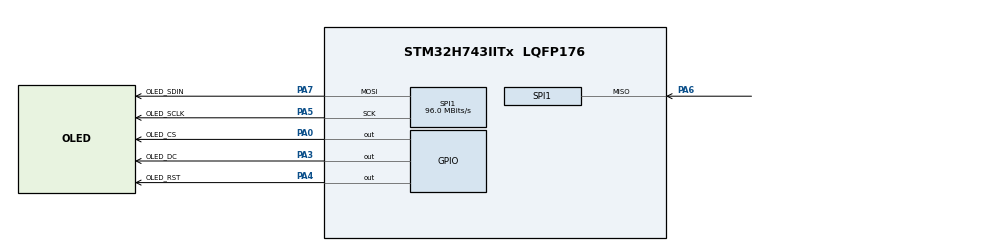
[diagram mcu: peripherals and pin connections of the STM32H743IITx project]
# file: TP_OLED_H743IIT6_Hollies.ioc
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ADC3.Channel-0\#ChannelRegularConversion=ADC_CHANNEL_TEMPSENSOR
ADC3.NbrOfConversion=1
ADC3.NbrOfConversionFlag=1
ADC3.OffsetNumber-0\#ChannelRegularConversion=ADC_OFFSET_NONE
ADC3.OffsetSignedSaturation-0\#ChannelRegularConversion=DISABLE
ADC3.Rank-0\#ChannelRegularConversion=1
ADC3.Resolution=ADC_RESOLUTION_16B
ADC3.SamplingTime-0\#ChannelRegularConversion=ADC_SAMPLETIME_810CYCLES_5
CORTEX_M7.AccessPermission_Spec=MPU_REGION_FULL_ACCESS
CORTEX_M7.BaseAddress_Spec=0x24000000
CORTEX_M7.CPU_DCache=Enabled
CORTEX_M7.CPU_ICache=Enabled
CORTEX_M7.DisableExec_Spec=MPU_INSTRUCTION_ACCESS_ENABLE
CORTEX_M7.IsBufferable_Spec=MPU_ACCESS_BUFFERABLE
CORTEX_M7.IsCacheable_Spec=MPU_ACCESS_CACHEABLE
CORTEX_M7.IsShareable_Spec=MPU_ACCESS_NOT_SHAREABLE
CORTEX_M7.Size_Spec=MPU_REGION_SIZE_512KB
CORTEX_M7.SubRegionDisable_Spec=0x0
CORTEX_M7.TypeExtField_Spec=MPU_TEX_LEVEL1
Mcu.Family=STM32H7
Mcu.Name=STM32H743IITx
Mcu.Package=LQFP176
NVIC.PriorityGroup=NVIC_PRIORITYGROUP_4
PA0.GPIO_Label=OLED_CS
PA0.GPIO_Speed=GPIO_SPEED_FREQ_VERY_HIGH
PA0.Signal=GPIO_Output
PA3.GPIO_Label=OLED_DC
PA3.GPIO_Speed=GPIO_SPEED_FREQ_VERY_HIGH
PA3.Signal=GPIO_Output
PA4.GPIO_Label=OLED_RST
PA4.GPIO_Speed=GPIO_SPEED_FREQ_VERY_HIGH
PA4.Signal=GPIO_Output
PA5.GPIO_Label=OLED_SCLK
PA5.GPIO_Speed=GPIO_SPEED_FREQ_VERY_HIGH
PA5.Mode=Full_Duplex_Master
PA5.Signal=SPI1_SCK
PA6.Mode=Full_Duplex_Master
PA6.Signal=SPI1_MISO
PA7.GPIO_Label=OLED_SDIN
PA7.GPIO_Speed=GPIO_SPEED_FREQ_VERY_HIGH
PA7.Mode=Full_Duplex_Master
PA7.Signal=SPI1_MOSI
PC14-OSC32_IN\ (OSC32_IN).Mode=LSE-External-Oscillator
PC14-OSC32_IN\ (OSC32_IN).Signal=RCC_OSC32_IN
PC15-OSC32_OUT\ (OSC32_OUT).Mode=LSE-External-Oscillator
PC15-OSC32_OUT\ (OSC32_OUT).Signal=RCC_OSC32_OUT
PH0-OSC_IN\ (PH0).Mode=HSE-External-Oscillator
PH0-OSC_IN\ (PH0).Signal=RCC_OSC_IN
PH1-OSC_OUT\ (PH1).Mode=HSE-External-Oscillator
PH1-OSC_OUT\ (PH1).Signal=RCC_OSC_OUT
ProjectManager.HeapSize=0x200
ProjectManager.StackSize=0x400
ProjectManager.TargetToolchain=STM32CubeIDE
RCC.ADCFreq_Value=75000000
RCC.APB1Freq_Value=120000000
RCC.APB2Freq_Value=120000000
RCC.APB3Freq_Value=120000000
RCC.APB4Freq_Value=120000000
RCC.CortexFreq_Value=480000000
RCC.D1PPRE=RCC_APB3_DIV2
RCC.D2PPRE1=RCC_APB1_DIV2
RCC.D2PPRE2=RCC_APB2_DIV2
RCC.D3PPRE=RCC_APB4_DIV2
RCC.DIVM1=5
RCC.DIVM2=2
RCC.DIVN1=192
RCC.DIVN2=12
RCC.DIVQ1=5
RCC.HCLKFreq_Value=240000000
RCC.HPRE=RCC_HCLK_DIV2
RCC.PLL2FRACN=0
RCC.PLLFRACN=0
RCC.PLLSourceVirtual=RCC_PLLSOURCE_HSE
RCC.SYSCLKFreq_VALUE=480000000
RCC.SYSCLKSource=RCC_SYSCLKSOURCE_PLLCLK
RCC.USBFreq_Value=192000000
SPI1.BaudRatePrescaler=SPI_BAUDRATEPRESCALER_2
SPI1.CLKPhase=SPI_PHASE_2EDGE
SPI1.CLKPolarity=SPI_POLARITY_HIGH
SPI1.CalculateBaudRate=96.0 MBits/s
SPI1.DataSize=SPI_DATASIZE_8BIT
SPI1.Direction=SPI_DIRECTION_2LINES
SPI1.Mode=SPI_MODE_MASTER
SPI1.NSSPMode=SPI_NSS_PULSE_DISABLE
SPI1.VirtualType=VM_MASTER
VP_ADC3_TempSens_Input.Mode=IN-TempSens
board=custom

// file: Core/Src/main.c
/* USER CODE BEGIN Header */
/**
  ******************************************************************************
  * @file           : main.c
  * @brief          : Main program body
  ******************************************************************************
  * @attention
  *
  * Copyright (c) 2023 STMicroelectronics.
  * All rights reserved.
  *
  * This software is licensed under terms that can be found in the LICENSE file
  * in the root directory of this software component.
  * If no LICENSE file comes with this software, it is provided AS-IS.
  *
  ******************************************************************************
  */
/* USER CODE END Header */
#include "main.h"
#include "adc.h"
#include "spi.h"
#include "gpio.h"

/* USER CODE BEGIN Includes */
#include "oled_spi.h"
#include "inter_temp.h"
#include <stdio.h>
/* USER CODE END Includes */

void SystemClock_Config(void);

int main(void)
{
  /* USER CODE BEGIN 1 */
	char temp[6] = "";
  /* USER CODE END 1 */
/* Enable the CPU Cache */

  /* Enable I-Cache---------------------------------------------------------*/
  SCB_EnableICache();

  /* Enable D-Cache---------------------------------------------------------*/
  SCB_EnableDCache();

  /* MCU Configuration--------------------------------------------------------*/

  /* Reset of all peripherals, Initializes the Flash interface and the Systick. */
  HAL_Init();

  /* Configure the system clock */
  SystemClock_Config();

  /* Initialize all configured peripherals */
  MX_GPIO_Init();
  MX_ADC3_Init();
  MX_SPI1_Init();
  /* USER CODE BEGIN 2 */
  OLED_Init();
  //ADC校准
  HAL_ADCEx_Calibration_Start(&hadc3,ADC_CALIB_OFFSET,ADC_SINGLE_ENDED);
  HAL_Delay(120);
  /* USER CODE END 2 */

  /* Infinite loop */
  while (1)
  {

    /* USER CODE BEGIN 3 */
	  sprintf(temp, "%.3f", getInterTemprature());
	  OLED_ShowString(0, 0, (uint8_t*)temp);
	  HAL_Delay(500);
  }
  /* USER CODE END 3 */
}

void SystemClock_Config(void)
{
  RCC_OscInitTypeDef RCC_OscInitStruct = {0};
  RCC_ClkInitTypeDef RCC_ClkInitStruct = {0};

  /** Supply configuration update enable
  */
  HAL_PWREx_ConfigSupply(PWR_LDO_SUPPLY);

  /** Configure the main internal regulator output voltage
  */
  __HAL_PWR_VOLTAGESCALING_CONFIG(PWR_REGULATOR_VOLTAGE_SCALE1);

  while(!__HAL_PWR_GET_FLAG(PWR_FLAG_VOSRDY)) {}

  __HAL_RCC_SYSCFG_CLK_ENABLE();
  __HAL_PWR_VOLTAGESCALING_CONFIG(PWR_REGULATOR_VOLTAGE_SCALE0);

  while(!__HAL_PWR_GET_FLAG(PWR_FLAG_VOSRDY)) {}

  /** Initializes the RCC Oscillators according to the specified parameters
  * in the RCC_OscInitTypeDef structure.
  */
  RCC_OscInitStruct.OscillatorType = RCC_OSCILLATORTYPE_HSE;
  RCC_OscInitStruct.HSEState = RCC_HSE_ON;
  RCC_OscInitStruct.PLL.PLLState = RCC_PLL_ON;
  RCC_OscInitStruct.PLL.PLLSource = RCC_PLLSOURCE_HSE;
  RCC_OscInitStruct.PLL.PLLM = 5;
  RCC_OscInitStruct.PLL.PLLN = 192;
  RCC_OscInitStruct.PLL.PLLP = 2;
  RCC_OscInitStruct.PLL.PLLQ = 5;
  RCC_OscInitStruct.PLL.PLLR = 2;
  RCC_OscInitStruct.PLL.PLLRGE = RCC_PLL1VCIRANGE_2;
  RCC_OscInitStruct.PLL.PLLVCOSEL = RCC_PLL1VCOWIDE;
  RCC_OscInitStruct.PLL.PLLFRACN = 0;
  if (HAL_RCC_OscConfig(&RCC_OscInitStruct) != HAL_OK)
  {
    Error_Handler();
  }

  /** Initializes the CPU, AHB and APB buses clocks
  */
  RCC_ClkInitStruct.ClockType = RCC_CLOCKTYPE_HCLK|RCC_CLOCKTYPE_SYSCLK
                              |RCC_CLOCKTYPE_PCLK1|RCC_CLOCKTYPE_PCLK2
                              |RCC_CLOCKTYPE_D3PCLK1|RCC_CLOCKTYPE_D1PCLK1;
  RCC_ClkInitStruct.SYSCLKSource = RCC_SYSCLKSOURCE_PLLCLK;
  RCC_ClkInitStruct.SYSCLKDivider = RCC_SYSCLK_DIV1;
  RCC_ClkInitStruct.AHBCLKDivider = RCC_HCLK_DIV2;
  RCC_ClkInitStruct.APB3CLKDivider = RCC_APB3_DIV2;
  RCC_ClkInitStruct.APB1CLKDivider = RCC_APB1_DIV2;
  RCC_ClkInitStruct.APB2CLKDivider = RCC_APB2_DIV2;
  RCC_ClkInitStruct.APB4CLKDivider = RCC_APB4_DIV2;

  if (HAL_RCC_ClockConfig(&RCC_ClkInitStruct, FLASH_LATENCY_4) != HAL_OK)
  {
    Error_Handler();
  }
}

void Error_Handler(void)
{
  __disable_irq();
  while (1)
  {
  }
}
